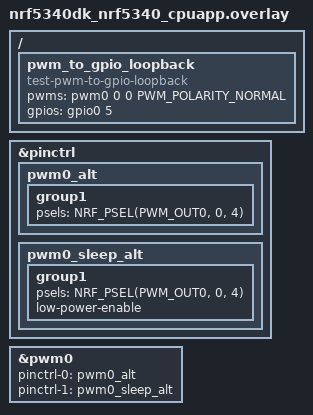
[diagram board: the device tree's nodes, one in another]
/*
 * Copyright (c) 2026 Nordic Semiconductor ASA
 *
 * SPDX-License-Identifier: LicenseRef-Nordic-5-Clause
 */

#include <zephyr/dt-bindings/pwm/pwm.h>
#include <zephyr/dt-bindings/gpio/nordic-nrf-gpio.h>

&pinctrl {
	pwm0_alt: pwm0_alt {
		group1 {
			psels = <NRF_PSEL(PWM_OUT0, 0, 4)>;
		};
	};

	pwm0_sleep_alt: pwm0_sleep_alt {
		group1 {
			psels = <NRF_PSEL(PWM_OUT0, 0, 4)>;
			low-power-enable;
		};
	};
};

&pwm0 {
	status = "okay";
	pinctrl-0 = <&pwm0_alt>;
	pinctrl-1 = <&pwm0_sleep_alt>;
	pinctrl-names = "default", "sleep";
};

/ {
	pwm_to_gpio_loopback: pwm_to_gpio_loopback {
		compatible = "test-pwm-to-gpio-loopback";
		pwms = <&pwm0 0 0 PWM_POLARITY_NORMAL>;
		gpios = <&gpio0 5 GPIO_ACTIVE_HIGH>;
	};
};
